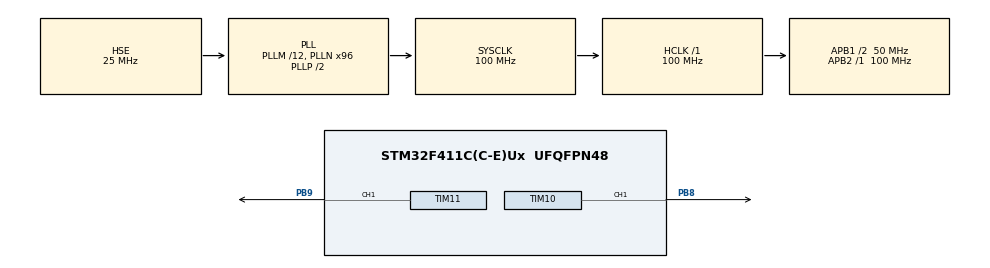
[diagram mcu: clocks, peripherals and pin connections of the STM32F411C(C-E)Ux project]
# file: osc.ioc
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Mcu.Family=STM32F4
RCC.PLLSourceVirtual=RCC_PLLSOURCE_HSE
TIM10.Prescaler=9
RCC.CortexFreq_Value=100000000
PH1\ -\ OSC_OUT.Mode=HSE-External-Oscillator
TIM11.Prescaler=99
RCC.APB1CLKDivider=RCC_HCLK_DIV2
RCC.SYSCLKSource=RCC_SYSCLKSOURCE_PLLCLK
ProjectManager.StackSize=0x400
VP_TIM11_VS_ClockSourceINT.Mode=Enable_Timer
PA13.Signal=SYS_JTMS-SWDIO
PH0\ -\ OSC_IN.Mode=HSE-External-Oscillator
PH0\ -\ OSC_IN.Signal=RCC_OSC_IN
ProjectManager.TargetToolchain=STM32CubeIDE
RCC.HCLKFreq_Value=100000000
RCC.APB2TimFreq_Value=100000000
VP_TIM10_VS_ClockSourceINT.Mode=Enable_Timer
RCC.LSE_VALUE=32768
RCC.AHBFreq_Value=100000000
RCC.HSE_VALUE=25000000
TIM11.Pulse=250
PH1\ -\ OSC_OUT.Signal=RCC_OSC_OUT
board=custom
RCC.VCOOutputFreq_Value=200000000
TIM10.Channel=TIM_CHANNEL_1
TIM11.Period=499
TIM10.Period=249
RCC.APB2Freq_Value=100000000
TIM10.Pulse=125
PA14.Mode=Serial_Wire
PA13.Mode=Serial_Wire
Mcu.Name=STM32F411C(C-E)Ux
RCC.48MHZClocksFreq_Value=50000000
RCC.SYSCLKFreq_VALUE=100000000
PB9.Signal=S_TIM11_CH1
Mcu.Package=UFQFPN48
SH.S_TIM10_CH1.0=TIM10_CH1,PWM Generation1 CH1
PA14.Signal=SYS_JTCK-SWCLK
ProjectManager.HeapSize=0x200
RCC.HSI_VALUE=16000000
NVIC.PriorityGroup=NVIC_PRIORITYGROUP_4
RCC.PLLM=12
RCC.PLLN=96
TIM11.Channel=TIM_CHANNEL_1
RCC.APB1TimFreq_Value=100000000
PB8.Signal=S_TIM10_CH1
RCC.APB1Freq_Value=50000000
SH.S_TIM11_CH1.0=TIM11_CH1,PWM Generation1 CH1
TIM10.OCFastMode_PWM=TIM_OCFAST_ENABLE

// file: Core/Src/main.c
/* USER CODE BEGIN Header */
/**
  ******************************************************************************
  * @file           : main.c
  * @brief          : Main program body
  ******************************************************************************
  * @attention
  *
  * <h2><center>&copy; Copyright (c) 2021 STMicroelectronics.
  * All rights reserved.</center></h2>
  *
  * This software component is licensed by ST under BSD 3-Clause license,
  * the "License"; You may not use this file except in compliance with the
  * License. You may obtain a copy of the License at:
  *                        opensource.org/licenses/BSD-3-Clause
  *
  ******************************************************************************
  */
/* USER CODE END Header */
#include "main.h"

TIM_HandleTypeDef htim10;
TIM_HandleTypeDef htim11;

void SystemClock_Config(void);
static void MX_GPIO_Init(void);
static void MX_TIM10_Init(void);
static void MX_TIM11_Init(void);

int main(void)
{

  /* MCU Configuration--------------------------------------------------------*/

  /* Reset of all peripherals, Initializes the Flash interface and the Systick. */
  HAL_Init();

  /* Configure the system clock */
  SystemClock_Config();

  /* Initialize all configured peripherals */
  MX_GPIO_Init();
  MX_TIM10_Init();
  MX_TIM11_Init();
  /* USER CODE BEGIN 2 */

  HAL_TIM_PWM_Start(&htim10, TIM_CHANNEL_1);
  HAL_TIM_PWM_Start(&htim11, TIM_CHANNEL_1);

  /* USER CODE END 2 */

  /* Infinite loop */
  while (1)
  {

  }
}

void SystemClock_Config(void)
{
  RCC_OscInitTypeDef RCC_OscInitStruct = {0};
  RCC_ClkInitTypeDef RCC_ClkInitStruct = {0};

  /** Configure the main internal regulator output voltage
  */
  __HAL_RCC_PWR_CLK_ENABLE();
  __HAL_PWR_VOLTAGESCALING_CONFIG(PWR_REGULATOR_VOLTAGE_SCALE1);
  /** Initializes the RCC Oscillators according to the specified parameters
  * in the RCC_OscInitTypeDef structure.
  */
  RCC_OscInitStruct.OscillatorType = RCC_OSCILLATORTYPE_HSE;
  RCC_OscInitStruct.HSEState = RCC_HSE_ON;
  RCC_OscInitStruct.PLL.PLLState = RCC_PLL_ON;
  RCC_OscInitStruct.PLL.PLLSource = RCC_PLLSOURCE_HSE;
  RCC_OscInitStruct.PLL.PLLM = 12;
  RCC_OscInitStruct.PLL.PLLN = 96;
  RCC_OscInitStruct.PLL.PLLP = RCC_PLLP_DIV2;
  RCC_OscInitStruct.PLL.PLLQ = 4;
  if (HAL_RCC_OscConfig(&RCC_OscInitStruct) != HAL_OK)
  {
    Error_Handler();
  }
  /** Initializes the CPU, AHB and APB buses clocks
  */
  RCC_ClkInitStruct.ClockType = RCC_CLOCKTYPE_HCLK|RCC_CLOCKTYPE_SYSCLK
                              |RCC_CLOCKTYPE_PCLK1|RCC_CLOCKTYPE_PCLK2;
  RCC_ClkInitStruct.SYSCLKSource = RCC_SYSCLKSOURCE_PLLCLK;
  RCC_ClkInitStruct.AHBCLKDivider = RCC_SYSCLK_DIV1;
  RCC_ClkInitStruct.APB1CLKDivider = RCC_HCLK_DIV2;
  RCC_ClkInitStruct.APB2CLKDivider = RCC_HCLK_DIV1;

  if (HAL_RCC_ClockConfig(&RCC_ClkInitStruct, FLASH_LATENCY_3) != HAL_OK)
  {
    Error_Handler();
  }
}

static void MX_TIM10_Init(void)
{

  TIM_OC_InitTypeDef sConfigOC = {0};

  htim10.Instance = TIM10;
  htim10.Init.Prescaler = 9;
  htim10.Init.CounterMode = TIM_COUNTERMODE_UP;
  htim10.Init.Period = 249;
  htim10.Init.ClockDivision = TIM_CLOCKDIVISION_DIV1;
  htim10.Init.AutoReloadPreload = TIM_AUTORELOAD_PRELOAD_DISABLE;
  if (HAL_TIM_Base_Init(&htim10) != HAL_OK)
  {
    Error_Handler();
  }
  if (HAL_TIM_PWM_Init(&htim10) != HAL_OK)
  {
    Error_Handler();
  }
  sConfigOC.OCMode = TIM_OCMODE_PWM1;
  sConfigOC.Pulse = 125;
  sConfigOC.OCPolarity = TIM_OCPOLARITY_HIGH;
  sConfigOC.OCFastMode = TIM_OCFAST_ENABLE;
  if (HAL_TIM_PWM_ConfigChannel(&htim10, &sConfigOC, TIM_CHANNEL_1) != HAL_OK)
  {
    Error_Handler();
  }
  HAL_TIM_MspPostInit(&htim10);

}

static void MX_TIM11_Init(void)
{

  TIM_OC_InitTypeDef sConfigOC = {0};

  htim11.Instance = TIM11;
  htim11.Init.Prescaler = 99;
  htim11.Init.CounterMode = TIM_COUNTERMODE_UP;
  htim11.Init.Period = 499;
  htim11.Init.ClockDivision = TIM_CLOCKDIVISION_DIV1;
  htim11.Init.AutoReloadPreload = TIM_AUTORELOAD_PRELOAD_DISABLE;
  if (HAL_TIM_Base_Init(&htim11) != HAL_OK)
  {
    Error_Handler();
  }
  if (HAL_TIM_PWM_Init(&htim11) != HAL_OK)
  {
    Error_Handler();
  }
  sConfigOC.OCMode = TIM_OCMODE_PWM1;
  sConfigOC.Pulse = 250;
  sConfigOC.OCPolarity = TIM_OCPOLARITY_HIGH;
  sConfigOC.OCFastMode = TIM_OCFAST_DISABLE;
  if (HAL_TIM_PWM_ConfigChannel(&htim11, &sConfigOC, TIM_CHANNEL_1) != HAL_OK)
  {
    Error_Handler();
  }
  HAL_TIM_MspPostInit(&htim11);

}

static void MX_GPIO_Init(void)
{

  /* GPIO Ports Clock Enable */
  __HAL_RCC_GPIOH_CLK_ENABLE();
  __HAL_RCC_GPIOA_CLK_ENABLE();
  __HAL_RCC_GPIOB_CLK_ENABLE();

}

void Error_Handler(void)
{
  __disable_irq();
  while (1)
  {
  }
}

/************************ (C) COPYRIGHT STMicroelectronics *****END OF FILE****/
